# R7FA4W1AD register map
Vendor: Renesas; Series: RA4; File version: 1.0
CPU: CM4 r0p1, little endian, MPU, FPU, VTOR, 4 interrupt priority bits
Registers are 8-bit, read-write, reset 0x0 unless marked. A register's access mark holds for its fields unless they carry their own. Offsets are from the block's base; [hi:lo] are bit positions; {n}, {i} and the like mark numbered series; 'fields as' and 'values as' point back to an identical list.

## CAC — Clock Frequency Accuracy Measurement Circuit
Base 0x40044600
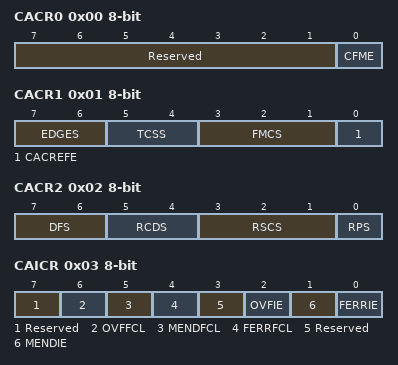
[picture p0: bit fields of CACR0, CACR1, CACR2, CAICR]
0x00 CACR0 — CAC Control Register 0
  [7:1] Reserved — These bits are read as 0000000. The write value should be 0000000.
  [0] CFME — Clock Frequency Measurement Enable.
    0=Disable; 1=Enable
0x01 CACR1 — CAC Control Register 1
  [7:6] EDGES — Valid Edge Select
    0=Rising edge; 1=Falling edge; 2=Both rising and falling edges; 3=Setting prohibited
  [5:4] TCSS — Measurement Target Clock Frequency Division Ratio Select
    0=No division; 1=x 1/4 clock; 2=x 1/8 clock; 3=x 1/32 clock
  [3:1] FMCS — Measurement Target Clock Select
    0=Main clock; 1=Sub-clock; 2=HOCO clock; 3=MOCO clock; 4=LOCO clock; 5=Peripheral module clock(PCLKB); 6=IWDTCLK clock; 7=Setting prohibited
  [0] CACREFE — CACREF Pin Input Enable
    0=Disable; 1=Enable
0x02 CACR2 — CAC Control Register 2
  [7:6] DFS — Digital Filter Selection
    0=Digital filtering is disabled; 1=The sampling clock for the digital filter is the frequency measuring clock; 2=The sampling clock for the digital filter is the frequency measuring clock divided by 4; 3=The sampling clock for the digital filter is the frequency measuring clock divided by 16
  [5:4] RCDS — Measurement Reference Clock Frequency Division Ratio Select
    0=1/32 clock; 1=1/128 clock; 2=1/1024 clock; 3=1/8192 clock
  [3:1] RSCS — Measurement Reference Clock Select
    values as CACR1.FMCS
  [0] RPS — Reference Signal Select
    0=CACREF pin input; 1=Internal clock (internally generated signal)
0x03 CAICR — CAC Interrupt Control Register
  [7] Reserved — This bit is read as 0. The write value should be 0.
  [6] OVFFCL wo — OVFF Clear
    0=No effect on operations; 1=Clears the OVFF flag
  [5] MENDFCL wo — MENDF Clear
    0=No effect on operations; 1=Clears the MENDF flag
  [4] FERRFCL wo — FERRF Clear
    0=No effect on operations; 1=Clears the FERRF flag
  [3] Reserved — This bit is read as 0. The write value should be 0.
  [2] OVFIE — Overflow Interrupt Request Enable
    0=Disable; 1=Enable
  [1] MENDIE — Measurement End Interrupt Request Enable
    0=Disable; 1=Enable
  [0] FERRIE — Frequency Error Interrupt Request Enable
    0=Disable; 1=Enable
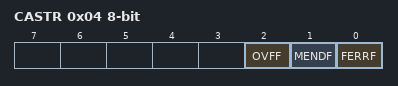
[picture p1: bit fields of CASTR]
0x04 CASTR ro — CAC Status Register
  [2] OVFF — Counter Overflow Flag
    0=The counter has not overflowed; 1=The counter has overflowed
  [1] MENDF — Measurement End Flag
    0=Measurement is in progress; 1=Measurement has ended
  [0] FERRF — Frequency Error Flag
    0=The clock frequency is within the range corresponding to the settings; 1=The clock frequency has deviated beyond the range corresponding to the settings (frequency error)
0x06 CAULVR 16-bit — CAC Upper-Limit Value Setting Register
  [15:0] CAULVR — CAULVR is a 16-bit readable/writable register that stores the upper-limit value of the frequency.
0x08 CALLVR 16-bit — CAC Lower-Limit Value Setting Register
  [15:0] CALLVR — CALLVR is a 16-bit readable/writable register that stores the lower-limit value of the frequency.
0x0A CACNTBR 16-bit ro — CAC Counter Buffer Register
  [15:0] CACNTBR — CACNTBR is a 16-bit read-only register that retains the counter value at the time a valid reference signal edge is input

## DAC8 — 8-bit D/A converter
Base 0x4009E000
{0x0+i} DACS{i} (i=0..1) — D/A Conversion Value Setting Register {i}
  [7:0] DACS — DACS D/A conversion store data note: When 8-bit D/A Converter output is selected as the reference input for the ACMPLP in the COMPSEL1 register, and ACMPLP operation is enabled (COMPMDR.CnENB = 1), changing the DACS[7:0] bits for the channel in use isprohibited.
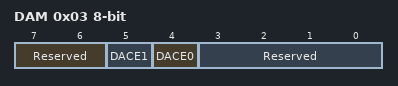
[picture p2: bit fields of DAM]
0x03 DAM — D/A Converter Mode Register
  [7:6] Reserved — These bits are read as 00. The write value should be 00.
  [5] DACE1 — D/A Operation Enable 1
    0=D/A conversion disabled for channel 1; 1=D/A conversion enabled for channel 1
  [4] DACE0 — D/A Operation Enable 0
    0=D/A conversion disabled for channel 0; 1=D/A conversion enabled for channel 0
  [3:0] Reserved — These bits are read as 0000. The write value should be 0000.
